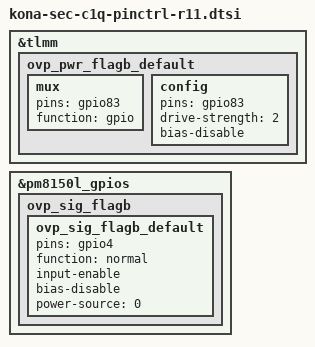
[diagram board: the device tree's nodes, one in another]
/* Copyright (c) 2020, The Linux Foundation. All rights reserved.
 *
 * This program is free software; you can redistribute it and/or modify
 * it under the terms of the GNU General Public License version 2 and
 * only version 2 as published by the Free Software Foundation.
 *
 * This program is distributed in the hope that it will be useful,
 * but WITHOUT ANY WARRANTY; without even the implied warranty of
 * MERCHANTABILITY or FITNESS FOR A PARTICULAR PURPOSE.  See the
 * GNU General Public License for more details.
 */

&tlmm {
	ovp_pwr_flagb_default: ovp_pwr_flagb_default{
		mux {
			pins = "gpio83";
			function = "gpio";
		};
		config {
			pins = "gpio83";
			drive-strength = <2>;
			bias-disable;
		};
	};
};

&pm8150l_gpios {
	ovp_sig_flagb { /* OVP_SIG_FLAGB */
		ovp_sig_flagb_default: ovp_sig_flagb_default {
			pins = "gpio4";
			function = "normal";
			input-enable;
			bias-disable;
			power-source = <0>;
		};
	};
};
